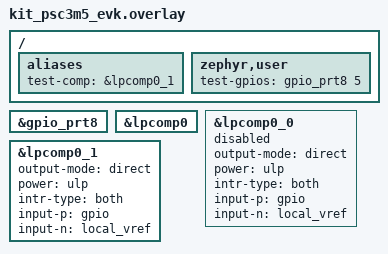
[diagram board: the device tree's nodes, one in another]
/*
 * Copyright (c) 2026 Infineon Technologies AG,
 * or an affiliate of Infineon Technologies AG.
 *
 * SPDX-License-Identifier: Apache-2.0
 */

/ {
	aliases {
		test-comp = &lpcomp0_1;
	};

	zephyr,user {
		/* P8.5 (the test pin) connects to P8.2 (input-p of the LPCOMP0_1) */
		test-gpios = <&gpio_prt8 5 0>;
	};
};

&gpio_prt8 {
	status = "okay";
};

&lpcomp0 {
	status = "okay";
};

&lpcomp0_0 {
	status = "disabled";
	output-mode = "direct";
	power = "ulp";
	intr-type = "both";
	input-p = "gpio";
	input-n = "local_vref";
};

&lpcomp0_1 {
	status = "okay";
	output-mode = "direct";
	power = "ulp";
	intr-type = "both";
	input-p = "gpio";
	input-n = "local_vref";
};
